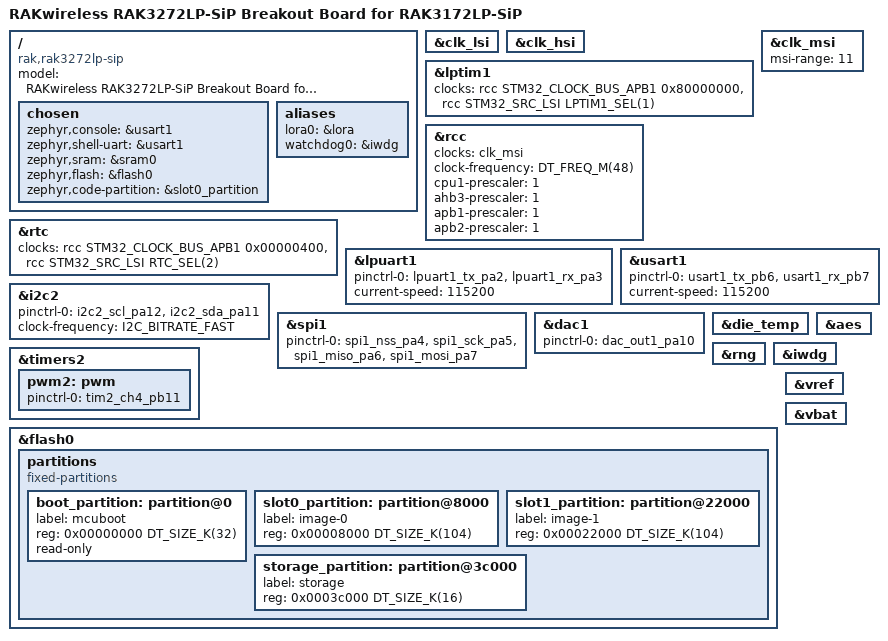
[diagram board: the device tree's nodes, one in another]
/*
 * Copyright (c) 2021 Thomas Stranger
 *
 * SPDX-License-Identifier: Apache-2.0
 */

/dts-v1/;
#include <rak/rak3172lp-sip.dtsi>
#include <zephyr/dt-bindings/input/input-event-codes.h>

/ {
	model = "RAKwireless RAK3272LP-SiP Breakout Board for RAK3172LP-SiP";
	compatible = "rak,rak3272lp-sip";

	chosen {
		zephyr,console = &usart1;
		zephyr,shell-uart = &usart1;
		zephyr,sram = &sram0;
		zephyr,flash = &flash0;
		zephyr,code-partition = &slot0_partition;
	};

	aliases {
		lora0 = &lora;
		watchdog0 = &iwdg;
	};
};


&clk_lsi {
	status = "okay";
};

&clk_hsi {
	status = "okay";
};

stm32_lp_tick_source: &lptim1 {
	clocks = <&rcc STM32_CLOCK_BUS_APB1 0x80000000>,
	         <&rcc STM32_SRC_LSI LPTIM1_SEL(1)>;
	status = "okay";
};

&clk_msi {
	status = "okay";
	msi-range = <11>;
};

&rcc {
	clocks = <&clk_msi>;
	clock-frequency = <DT_FREQ_M(48)>;
	cpu1-prescaler = <1>;
	ahb3-prescaler = <1>;
	apb1-prescaler = <1>;
	apb2-prescaler = <1>;
};

&rtc {
	clocks = <&rcc STM32_CLOCK_BUS_APB1 0x00000400>,
	         <&rcc STM32_SRC_LSI RTC_SEL(2)>;
	status = "okay";
};

&lpuart1 {
	pinctrl-0 = <&lpuart1_tx_pa2 &lpuart1_rx_pa3>;
	pinctrl-names = "default";
	current-speed = <115200>;
	status = "okay";
};

&usart1 {
	pinctrl-0 = <&usart1_tx_pb6 &usart1_rx_pb7>;
	pinctrl-names = "default";
	current-speed = <115200>;
	status = "okay";
};

&i2c2 {
	pinctrl-0 = <&i2c2_scl_pa12 &i2c2_sda_pa11>;
	pinctrl-names = "default";
	status = "okay";
	clock-frequency = <I2C_BITRATE_FAST>;
};

&spi1 {
	pinctrl-0 = <&spi1_nss_pa4 &spi1_sck_pa5
	&spi1_miso_pa6 &spi1_mosi_pa7>;
	pinctrl-names = "default";
	status = "okay";
};


&dac1 {
	pinctrl-0 = <&dac_out1_pa10>;
	pinctrl-names = "default";
	status = "okay";
};

&timers2 {
	status = "okay";
	pwm2: pwm {
		status = "okay";
		pinctrl-0 = <&tim2_ch4_pb11>;
		pinctrl-names = "default";
	};
};

&die_temp {
	status = "okay";
};

&aes {
	status = "okay";
};

&rng {
	status = "okay";
};

&iwdg {
	status = "okay";
};

&flash0 {
	partitions {
		compatible = "fixed-partitions";
		#address-cells = <1>;
		#size-cells = <1>;

		boot_partition: partition@0 {
			label = "mcuboot";
			reg = <0x00000000 DT_SIZE_K(32)>;
			read-only;
		};
		slot0_partition: partition@8000 {
			label = "image-0";
			reg = <0x00008000 DT_SIZE_K(104)>;
		};
		slot1_partition: partition@22000 {
			label = "image-1";
			reg = <0x00022000 DT_SIZE_K(104)>;
		};

		/*
		 * Set 16kB of storage (8x2kB pages) at the end of the 256kB of
		 * flash.
		 */
		storage_partition: partition@3c000 {
			label = "storage";
			reg = <0x0003c000 DT_SIZE_K(16)>;
		};
	};
};

&vref {
	status = "okay";
};

&vbat {
	status = "okay";
};
